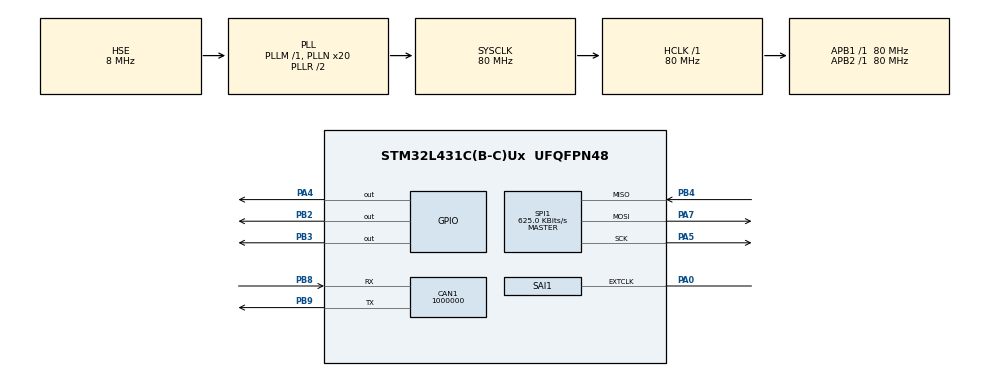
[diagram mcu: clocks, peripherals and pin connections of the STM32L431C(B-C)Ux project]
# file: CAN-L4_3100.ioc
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CAN1.BS1=CAN_BS1_3TQ
CAN1.CalculateBaudRate=1000000
CAN1.CalculateTimeBit=1000
CAN1.CalculateTimeQuantum=200.0
FREERTOS.Tasks01=defaultTask,24,128,StartDefaultTask,Default,NULL,Dynamic,NULL,NULL
FREERTOS.configUSE_TICK_HOOK=1
Mcu.Family=STM32L4
Mcu.Name=STM32L431C(B-C)Ux
Mcu.Package=UFQFPN48
NVIC.CAN1_RX0_IRQn=true\:5\:0\:false\:false\:true\:true\:true\:true\:true
NVIC.CAN1_SCE_IRQn=true\:5\:0\:false\:false\:true\:true\:true\:true\:true
NVIC.CAN1_TX_IRQn=true\:5\:0\:false\:false\:true\:true\:true\:true\:true
NVIC.PriorityGroup=NVIC_PRIORITYGROUP_4
NVIC.SPI1_IRQn=true\:5\:0\:false\:false\:true\:true\:true\:true\:true
PA0.Mode=Audio_ClockInSAI1
PA0.Signal=SAI1_EXTCLK
PA13\ (JTMS-SWDIO).Mode=Serial_Wire
PA13\ (JTMS-SWDIO).Signal=SYS_JTMS-SWDIO
PA14\ (JTCK-SWCLK).Mode=Serial_Wire
PA14\ (JTCK-SWCLK).Signal=SYS_JTCK-SWCLK
PA4.Signal=GPIO_Output
PA5.Mode=Full_Duplex_Master
PA5.Signal=SPI1_SCK
PA7.Mode=Full_Duplex_Master
PA7.Signal=SPI1_MOSI
PB2.Signal=GPIO_Output
PB3\ (JTDO-TRACESWO).Signal=GPIO_Output
PB4\ (NJTRST).Mode=Full_Duplex_Master
PB4\ (NJTRST).Signal=SPI1_MISO
PB8.Mode=CAN_Activate
PB8.Signal=CAN1_RX
PB9.Mode=CAN_Activate
PB9.Signal=CAN1_TX
PH0-OSC_IN\ (PH0).Mode=HSE-External-Oscillator
PH0-OSC_IN\ (PH0).Signal=RCC_OSC_IN
PH1-OSC_OUT\ (PH1).Mode=HSE-External-Oscillator
PH1-OSC_OUT\ (PH1).Signal=RCC_OSC_OUT
ProjectManager.HeapSize=0x200
ProjectManager.StackSize=0x400
ProjectManager.TargetToolchain=STM32CubeIDE
RCC.ADCFreq_Value=32000000
RCC.AHBFreq_Value=80000000
RCC.APB1Freq_Value=80000000
RCC.APB1TimFreq_Value=80000000
RCC.APB2Freq_Value=80000000
RCC.APB2TimFreq_Value=80000000
RCC.CortexFreq_Value=80000000
RCC.HCLKFreq_Value=80000000
RCC.HSE_VALUE=8000000
RCC.HSI48_VALUE=48000000
RCC.HSI_VALUE=16000000
RCC.LSE_VALUE=32768
RCC.MSI_VALUE=4000000
RCC.PLLN=20
RCC.PLLSourceVirtual=RCC_PLLSOURCE_HSE
RCC.SYSCLKFreq_VALUE=80000000
RCC.SYSCLKSource=RCC_SYSCLKSOURCE_PLLCLK
RCC.VCOOutputFreq_Value=160000000
SPI1.BaudRatePrescaler=SPI_BAUDRATEPRESCALER_128
SPI1.CalculateBaudRate=625.0 KBits/s
SPI1.DataSize=SPI_DATASIZE_8BIT
SPI1.Direction=SPI_DIRECTION_2LINES
SPI1.Mode=SPI_MODE_MASTER
SPI1.VirtualType=VM_MASTER
VP_FREERTOS_VS_CMSIS_V2.Mode=CMSIS_V2
board=custom

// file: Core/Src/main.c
/* USER CODE BEGIN Header */
/**
  ******************************************************************************
  * @file           : main.c
  * @brief          : Main program body
  ******************************************************************************
  * @attention
  *
  * Copyright (c) 2025 STMicroelectronics.
  * All rights reserved.
  *
  * This software is licensed under terms that can be found in the LICENSE file
  * in the root directory of this software component.
  * If no LICENSE file comes with this software, it is provided AS-IS.
  *
  ******************************************************************************
  */
/* USER CODE END Header */
#include "main.h"
#include "cmsis_os.h"

CAN_HandleTypeDef hcan1;

SPI_HandleTypeDef hspi1;

/* Definitions for defaultTask */
osThreadId_t defaultTaskHandle;
const osThreadAttr_t defaultTask_attributes = {
  .name = "defaultTask",
  .stack_size = 128 * 4,
  .priority = (osPriority_t) osPriorityNormal,
};

void SystemClock_Config(void);
static void MX_GPIO_Init(void);
static void MX_CAN1_Init(void);
static void MX_SPI1_Init(void);
void StartDefaultTask(void *argument);

/* USER CODE BEGIN 0 */

void RM3100_runnable( void * nix);
osThreadId_t RM3100_TaskHandle;

/* USER CODE END 0 */

int main(void)
{

  /* MCU Configuration--------------------------------------------------------*/

  /* Reset of all peripherals, Initializes the Flash interface and the Systick. */
  HAL_Init();

  /* Configure the system clock */
  SystemClock_Config();

  /* Initialize all configured peripherals */
  MX_GPIO_Init();
  MX_CAN1_Init();
  MX_SPI1_Init();

  /* Init scheduler */
  osKernelInitialize();

  /* Create the thread(s) */
  /* creation of defaultTask */
  defaultTaskHandle = osThreadNew(StartDefaultTask, NULL, &defaultTask_attributes);

  /* USER CODE BEGIN RTOS_THREADS */
  /* add threads, ... */
//  RM3100_TaskHandle = osThreadNew( RM3100_runnable, NULL, &defaultTask_attributes);
  /* USER CODE END RTOS_THREADS */

  /* Start scheduler */
  osKernelStart();

  /* We should never get here as control is now taken by the scheduler */

  /* Infinite loop */
  while (1)
  {

    /* USER CODE BEGIN 3 */
	  asm("bkpt 0"); // never come here ...
  }
  /* USER CODE END 3 */
}

void SystemClock_Config(void)
{
  RCC_OscInitTypeDef RCC_OscInitStruct = {0};
  RCC_ClkInitTypeDef RCC_ClkInitStruct = {0};

  /** Configure the main internal regulator output voltage
  */
  if (HAL_PWREx_ControlVoltageScaling(PWR_REGULATOR_VOLTAGE_SCALE1) != HAL_OK)
  {
    Error_Handler();
  }

  /** Initializes the RCC Oscillators according to the specified parameters
  * in the RCC_OscInitTypeDef structure.
  */
  RCC_OscInitStruct.OscillatorType = RCC_OSCILLATORTYPE_HSE;
  RCC_OscInitStruct.HSEState = RCC_HSE_ON;
  RCC_OscInitStruct.PLL.PLLState = RCC_PLL_ON;
  RCC_OscInitStruct.PLL.PLLSource = RCC_PLLSOURCE_HSE;
  RCC_OscInitStruct.PLL.PLLM = 1;
  RCC_OscInitStruct.PLL.PLLN = 20;
  RCC_OscInitStruct.PLL.PLLP = RCC_PLLP_DIV7;
  RCC_OscInitStruct.PLL.PLLQ = RCC_PLLQ_DIV2;
  RCC_OscInitStruct.PLL.PLLR = RCC_PLLR_DIV2;
  if (HAL_RCC_OscConfig(&RCC_OscInitStruct) != HAL_OK)
  {
    Error_Handler();
  }

  /** Initializes the CPU, AHB and APB buses clocks
  */
  RCC_ClkInitStruct.ClockType = RCC_CLOCKTYPE_HCLK|RCC_CLOCKTYPE_SYSCLK
                              |RCC_CLOCKTYPE_PCLK1|RCC_CLOCKTYPE_PCLK2;
  RCC_ClkInitStruct.SYSCLKSource = RCC_SYSCLKSOURCE_PLLCLK;
  RCC_ClkInitStruct.AHBCLKDivider = RCC_SYSCLK_DIV1;
  RCC_ClkInitStruct.APB1CLKDivider = RCC_HCLK_DIV1;
  RCC_ClkInitStruct.APB2CLKDivider = RCC_HCLK_DIV1;

  if (HAL_RCC_ClockConfig(&RCC_ClkInitStruct, FLASH_LATENCY_4) != HAL_OK)
  {
    Error_Handler();
  }
}

static void MX_CAN1_Init(void)
{

  hcan1.Instance = CAN1;
  hcan1.Init.Prescaler = 16;
  hcan1.Init.Mode = CAN_MODE_NORMAL;
  hcan1.Init.SyncJumpWidth = CAN_SJW_1TQ;
  hcan1.Init.TimeSeg1 = CAN_BS1_3TQ;
  hcan1.Init.TimeSeg2 = CAN_BS2_1TQ;
  hcan1.Init.TimeTriggeredMode = DISABLE;
  hcan1.Init.AutoBusOff = DISABLE;
  hcan1.Init.AutoWakeUp = DISABLE;
  hcan1.Init.AutoRetransmission = DISABLE;
  hcan1.Init.ReceiveFifoLocked = DISABLE;
  hcan1.Init.TransmitFifoPriority = DISABLE;
  if (HAL_CAN_Init(&hcan1) != HAL_OK)
  {
    Error_Handler();
  }

}

static void MX_SPI1_Init(void)
{

  /* SPI1 parameter configuration*/
  hspi1.Instance = SPI1;
  hspi1.Init.Mode = SPI_MODE_MASTER;
  hspi1.Init.Direction = SPI_DIRECTION_2LINES;
  hspi1.Init.DataSize = SPI_DATASIZE_8BIT;
  hspi1.Init.CLKPolarity = SPI_POLARITY_LOW;
  hspi1.Init.CLKPhase = SPI_PHASE_1EDGE;
  hspi1.Init.NSS = SPI_NSS_SOFT;
  hspi1.Init.BaudRatePrescaler = SPI_BAUDRATEPRESCALER_128;
  hspi1.Init.FirstBit = SPI_FIRSTBIT_MSB;
  hspi1.Init.TIMode = SPI_TIMODE_DISABLE;
  hspi1.Init.CRCCalculation = SPI_CRCCALCULATION_DISABLE;
  hspi1.Init.CRCPolynomial = 7;
  hspi1.Init.CRCLength = SPI_CRC_LENGTH_DATASIZE;
  hspi1.Init.NSSPMode = SPI_NSS_PULSE_ENABLE;
  if (HAL_SPI_Init(&hspi1) != HAL_OK)
  {
    Error_Handler();
  }

}

static void MX_GPIO_Init(void)
{
  GPIO_InitTypeDef GPIO_InitStruct = {0};

  /* GPIO Ports Clock Enable */
  __HAL_RCC_GPIOH_CLK_ENABLE();
  __HAL_RCC_GPIOA_CLK_ENABLE();
  __HAL_RCC_GPIOB_CLK_ENABLE();

  /*Configure GPIO pin Output Level */
  HAL_GPIO_WritePin(GPIOA, GPIO_PIN_4, GPIO_PIN_SET); // NSS inactive

  /*Configure GPIO pin Output Level */
  HAL_GPIO_WritePin(GPIOB, GPIO_PIN_2|GPIO_PIN_3, GPIO_PIN_SET);

  /*Configure GPIO pin : PA0 */
  GPIO_InitStruct.Pin = GPIO_PIN_0;
  GPIO_InitStruct.Mode = GPIO_MODE_AF_PP;
  GPIO_InitStruct.Pull = GPIO_NOPULL;
  GPIO_InitStruct.Speed = GPIO_SPEED_FREQ_LOW;
  GPIO_InitStruct.Alternate = GPIO_AF13_SAI1;
  HAL_GPIO_Init(GPIOA, &GPIO_InitStruct);

  /*Configure GPIO pin : PA4 */
  GPIO_InitStruct.Pin = GPIO_PIN_4;
  GPIO_InitStruct.Mode = GPIO_MODE_OUTPUT_PP;
  GPIO_InitStruct.Pull = GPIO_NOPULL;
  GPIO_InitStruct.Speed = GPIO_SPEED_FREQ_LOW;
  HAL_GPIO_Init(GPIOA, &GPIO_InitStruct);

  /*Configure GPIO pins : PB2 PB3 */
  GPIO_InitStruct.Pin = GPIO_PIN_2|GPIO_PIN_3;
  GPIO_InitStruct.Mode = GPIO_MODE_OUTPUT_PP;
  GPIO_InitStruct.Pull = GPIO_NOPULL;
  GPIO_InitStruct.Speed = GPIO_SPEED_FREQ_LOW;
  HAL_GPIO_Init(GPIOB, &GPIO_InitStruct);

}

void StartDefaultTask(void *argument)
{
  /* USER CODE BEGIN 5 */
  for(;;)
  {
    osDelay(500);
    HAL_GPIO_WritePin(GPIOB, GPIO_PIN_3, GPIO_PIN_RESET);
    osDelay(500);
    HAL_GPIO_WritePin(GPIOB, GPIO_PIN_3, GPIO_PIN_SET);
  }
  /* USER CODE END 5 */
}

void Error_Handler(void)
{
  /* USER CODE BEGIN Error_Handler_Debug */
  /* User can add his own implementation to report the HAL error return state */
  __disable_irq();
  while (1)
	  asm("bkpt 0");

  /* USER CODE END Error_Handler_Debug */
}
